# STM32F730 register map
File version: 1.5
CPU: CM7 r0p1, little endian, MPU, FPU, 4 interrupt priority bits
Registers are 32-bit, read-write, reset 0x0 unless marked. A register's access mark holds for its fields unless they carry their own. Offsets are from the block's base; [hi:lo] are bit positions; {n}, {i} and the like mark numbered series.

## TIM6 — Basic timers
Base 0x40001000
Same registers: TIM7 0x40001400
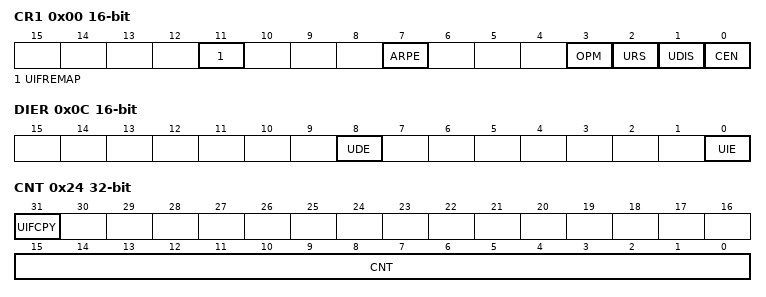
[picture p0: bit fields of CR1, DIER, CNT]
0x00 CR1 16-bit — control register 1
  [11] UIFREMAP — UIF status bit remapping
  [7] ARPE — Auto-reload preload enable
    0=Disabled (TIMx_APRR register is not buffered); 1=Enabled (TIMx_APRR register is buffered)
  [3] OPM — One-pulse mode
    0=Disabled (Counter is not stopped at update event); 1=Enabled (Counter stops counting at the next update event (clearing the CEN bit))
  [2] URS — Update request source
    0=AnyEvent (Any of counter overflow/underflow, setting UG, or update through slave mode, generates an update interrupt or DMA request); 1=CounterOnly (Only counter overflow/underflow generates an update interrupt or DMA request)
  [1] UDIS — Update disable
    0=Enabled (Update event enabled); 1=Disabled (Update event disabled)
  [0] CEN — Counter enable
    0=Disabled (Counter disabled); 1=Enabled (Counter enabled)
0x04 CR2 16-bit — control register 2
  [6:4] MMS — Master mode selection
    0=Reset (Use UG bit from TIMx_EGR register); 1=Enable (Use CNT bit from TIMx_CEN register); 2=Update (Use the update event)
0x0C DIER 16-bit — DMA/Interrupt enable register
  [8] UDE — Update DMA request enable
    0=Disabled (Update DMA request disabled); 1=Enabled (Update DMA request enabled)
  [0] UIE — Update interrupt enable
    0=Disabled (Update interrupt disabled); 1=Enabled (Update interrupt enabled)
0x10 SR 16-bit — status register
  [0] UIF write-0-clears — Update interrupt flag
    on read: 0=NoUpdateOccurred; 1=UpdatePending (Update interrupt pending) | on write: 0=Clear flag
0x14 EGR wo — event generation register
  [0] UG — Update generation
    1=Update (Re-initializes the timer counter and generates an update of the registers.)
0x24 CNT access per field — counter
  [31] UIFCPY ro — UIF Copy
  [15:0] CNT rw — Low counter value
0x24 CNT16 16-bit (alternate view of CNT) — 16-bit counter register
  [15:0] CNT — counter value
0x28 PSC 16-bit — prescaler
  [15:0] PSC — Prescaler value
0x2C ARR 16-bit reset 0xFFFF — auto-reload register
  [15:0] ARR — Low Auto-reload value

## CRC — Cryptographic processor
Base 0x40023000
0x00 DR reset 0xFFFFFFFF — Data register
  [31:0] DR — Data Register
0x00 DR8 8-bit reset 0xFF (alternate view of DR) — Data register - byte sized
  [7:0] DR8 — Data register bits
0x00 DR16 16-bit reset 0xFFFF (alternate view of DR) — Data register - half-word sized
  [15:0] DR16 — Data register bits
0x04 IDR — Independent Data register
  [7:0] IDR
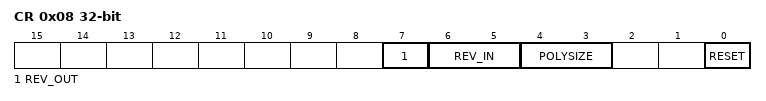
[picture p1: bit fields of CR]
0x08 CR wo — Control register
  [7] REV_OUT — Reverse output data
    0=Normal (Bit order not affected); 1=Reversed (Bit reversed output)
  [6:5] REV_IN — Reverse input data
    0=Normal (Bit order not affected); 1=Byte (Bit reversal done by byte); 2=HalfWord (Bit reversal done by half-word); 3=Word (Bit reversal done by word)
  [4:3] POLYSIZE — Polynomial size
    0=32-bit polynomial; 1=16-bit polynomial; 2=8-bit polynomial; 3=7-bit polynomial
  [0] RESET — RESET bit
    1=Resets the CRC calculation unit and sets the data register to 0xFFFF FFFF
0x10 INIT — Initial CRC value
  [31:0] INIT — Programmable initial CRC value
0x14 POL — CRC polynomial
  [31:0] POL — Programmable polynomial

## DBGMCU — Debug support
Base 0xE0042000
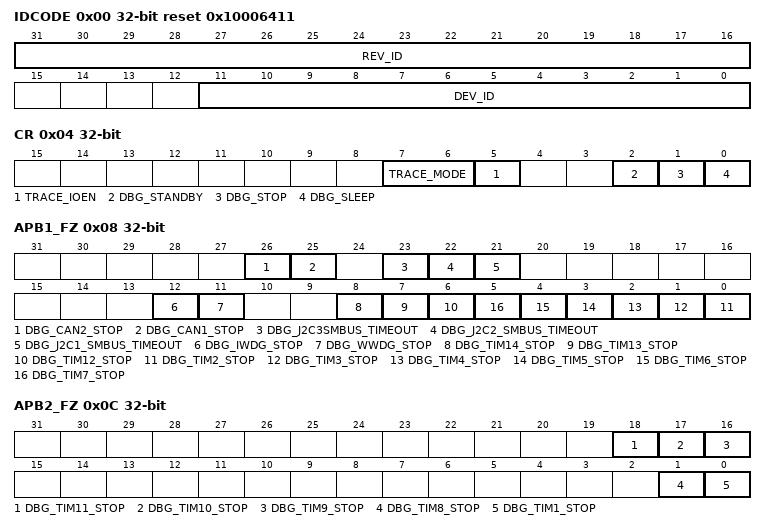
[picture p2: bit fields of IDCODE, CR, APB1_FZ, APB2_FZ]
0x00 IDCODE ro reset 0x10006411
  [31:16] REV_ID, [11:0] DEV_ID
0x04 CR — Control Register
  [7:6] TRACE_MODE, [5] TRACE_IOEN, [2] DBG_STANDBY, [1] DBG_STOP, [0] DBG_SLEEP
0x08 APB1_FZ — Debug MCU APB1 Freeze registe
  [26] DBG_CAN2_STOP
  [25] DBG_CAN1_STOP
  [23] DBG_J2C3SMBUS_TIMEOUT
  [22] DBG_J2C2_SMBUS_TIMEOUT
  [21] DBG_J2C1_SMBUS_TIMEOUT
  [12] DBG_IWDG_STOP — DBG_IWDEG_STOP
  [11] DBG_WWDG_STOP
  [8] DBG_TIM14_STOP
  [7] DBG_TIM13_STOP
  [6] DBG_TIM12_STOP
  [n-2] DBG_TIM{n}_STOP (n=2..7)
0x0C APB2_FZ — Debug MCU APB2 Freeze registe
  [18] DBG_TIM11_STOP — TIM11 counter stopped when core is halted
  [17] DBG_TIM10_STOP — TIM10 counter stopped when core is halted
  [16] DBG_TIM9_STOP — TIM9 counter stopped when core is halted
  [1] DBG_TIM8_STOP — TIM8 counter stopped when core is halted
  [0] DBG_TIM1_STOP — TIM1 counter stopped when core is halted
